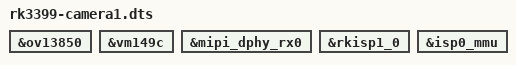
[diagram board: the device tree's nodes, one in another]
/dts-v1/;
/plugin/;

/ {
	fragment@0 {
		target = <&ov13850>;
		__overlay__ {
			status = "okay";
		};
	};

	fragment@1 {
		target = <&vm149c>;
		__overlay__ {
			status = "okay";
		};
	};

	fragment@2 {
		target = <&mipi_dphy_rx0>;
		__overlay__ {
			status = "okay";
		};
	};

	fragment@3 {
		target = <&rkisp1_0>;
		__overlay__ {
			status = "okay";
		};
	};

	fragment@4 {
		target = <&isp0_mmu>;
		__overlay__ {
			status = "okay";
		};
	};
};
